# CEC1712H_S2_SX device description
Architecture: CORTEX-M4; Family: CEC1712H_S2_SX; Series: CEC1712H_S2_SX
Registers are 32-bit, read-write, reset 0x0 unless marked. A register's access mark holds for its fields unless they carry their own. Offsets are from the block's base; [hi:lo] are bit positions.

## WEEK — The Week Timer and the Sub-Week Timer assert the Power-Up Event Output which automatically powers-up the system from the G3 state
Instances: WEEK 0x4000AC80
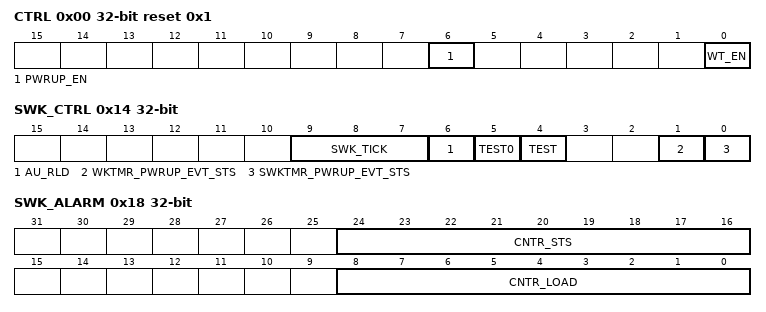
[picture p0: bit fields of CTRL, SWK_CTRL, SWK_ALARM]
0x00 CTRL reset 0x1 — Control Register
  [6] PWRUP_EN — This bit controls the state of the Power-Up Event Output and enables Week POWER-UP Event decoding in the VBAT-Powered Control Interface. 1=Power-Up Event Output Enabled. 0=Power-Up Event Output Disabled and Reset
  [0] WT_EN — The WT_ENABLE bit is used to start and stop the Week Alarm Counter Register and the Clock Divider Register. The value in the Counter Register is held when the WT_ENABLE bit is not asserted (0) and the count is resumed from the last value when the bit is asserted (1). The 15-Bit Clock Divider is reset to 00h and the Week Alarm Interface is in its lowest power consumption state when the WT_ENABLE bit is not asserted.
0x04 ALARM_CNT — Week Alarm Counter Register
  [27:0] WK_CNTR — While the WT_ENABLE bit is 1, this register is incremented at a 1 Hz rate. Writes of this register may require one second to take effect. Reads return the current state of the register. Reads and writes complete independently of the state of WT_ENABLE.
0x08 TMR_COMP reset 0xFFFFFFF — Week Timer Compare Register
  [27:0] WK_COMP — A Week Alarm Interrupt and a Week Alarm Power-Up Event are asserted when the Week Alarm Counter Register is greater than or equal to the contents of this register. Reads and writes complete independently of the state of WT_ENABLE.
0x0C CLKDIV — Clock Divider Register
  [14:0] DIV — Reads of this register return the current state of the Week Timer 15- bit clock divider.
0x10 SS_INTR_SEL — Sub-Second Programmable Interrupt Select Register
  [3:0] SPISR — This field determines the rate at which Sub-Second interrupt events are generated.
0x14 SWK_CTRL ro — Sub-Week Control Register
  [9:7] SWK_TICK — This field selects the clock source for the Sub-Week Counter.
  [6] AU_RLD — 1= No reload occurs when the Sub-Week Counter expires. 0= Reloads the SUBWEEK_COUNTER_LOAD field into the Sub- Week Counter when the counter expires.
  [5] TEST0 — Test
  [4] TEST
  [1] WKTMR_PWRUP_EVT_STS — This bit is set to 1 when the Week Alarm Counter Register is greater than or equal the contents of the Week Timer Compare. Register and the POWERUP_EN is 1. Writes of 1 clear this bit. Writes of 0 have no effect. Note: This bit does not have to be cleared to remove a Week Timer Power-Up Event.
  [0] SWKTMR_PWRUP_EVT_STS — This bit is set to 1 when the Sub-Week Alarm Counter Register decrements from 1 to 0 and the POWERUP_EN is 1. Writes of 1 clear this bit. Writes of 0 have no effect. Note: This bit MUST be cleared to remove a Sub-Week Timer Power-Up Event.
0x18 SWK_ALARM ro — Sub-Week Alarm Counter Register
  [24:16] CNTR_STS — Reads of this register return the current state of the 9-bit Sub-Week Alarm counter.
  [8:0] CNTR_LOAD — Writes with a non-zero value to this field reload the 9-bit Sub-Week Alarm counter. Writes of 0 disable the counter. If the Sub-Week Alarm counter decrements to 0 and the AUTO_RELOAD bit is set, the value in this field is automatically loaded into the Sub-Week Alarm counter.

## TACH — This block monitors TACH output signals from various types of fans, and determines their speed.
Instances: TACH0 0x40006000, TACH1 0x40006010
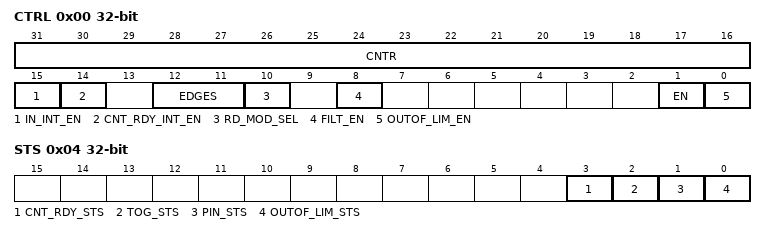
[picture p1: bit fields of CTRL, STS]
0x00 CTRL — TACHx Control Register
  [31:16] CNTR — This 16-bit field contains the latched value of the internal Tach pulse counter, which may be configured by the Tach Reading Mode Select field to operate as a free-running counter or to be gated by the Tach input signal.
  [15] IN_INT_EN — TACH_INPUT_INT_EN 1=Enable Tach Input toggle interrupt from Tach block, 0=Disable Tach Input toggle interrupt from Tach block
  [14] CNT_RDY_INT_EN — COUNT_READY_INT_EN 1=Enable Count Ready interrupt from Tach block, 0=Disable Count Ready interrupt from Tach block
  [12:11] EDGES — TACH_EDGES A Tach signal is a square wave with a 50 percent duty cycle. Typically, two Tach periods represents one revolution of the fan. A Tach period consists of three Tach edges. This programmed value represents the number of Tach edges that will be used to determine the interval for which the number of 100kHz_Clk pulses will be counted. 11b=9 Tach edges (4 Tach periods). 10b=5 Tach edges (2 Tach periods). 01b=3 Tach edges (1 Tach period). 00b=2 Tach edges (1/2 Tach period)
  [10] RD_MOD_SEL — TACH_READING_MODE_SELECT. 1=Counter is incremented on the rising edge of the 100kHz_Clk input. The counter is latched into the TACHX_COUNTER field and reset when the programmed number of edges is detected. 0=Counter is incremented when Tach Input transitions from low-tohigh state (default)
  [8] FILT_EN — FILTER_ENABLE This filter is used to remove high frequency glitches from Tach Input. When this filter is enabled, Tach input pulses less than two 100kHz_- Clk periods wide get filtered. 1= Filter enabled. 0= Filter disabled (default). It is recommended that the Tach input filter always be enabled.
  [1] EN — TACH_ENABLE 1= TACH Monitoring enabled, clocks enabled. 0= TACH Idle, clocks gated
  [0] OUTOF_LIM_EN — TACH_OUT_OF_LIMIT_ENABLE This bit is used to enable the TACH_OUT_OF_LIMIT_STATUS bit in the TACHx Status Register to generate an interrupt event. 1=Enable interrupt output from Tach block. 0=Disable interrupt output from Tach block (default)
0x04 STS — TACHx Status Register
  [3] CNT_RDY_STS — COUNT_READY_STATUS 1=Reading ready, 0=Reading not ready
  [2] TOG_STS — TOGGLE_STATUS 1=Tach Input changed state (this bit is set on a low-to-high or high-tolow transition), 0=Tach stable (R/WC)
  [1] PIN_STS — TACH_PIN_STATUS 1= Tach Input is high, 0= Tach Input is low
  [0] OUTOF_LIM_STS — TACH_OUT_OF_LIMIT_STATUS 1=Tach is outside of limits, 0=Tach is within limits (R/WC)
0x08 LIM_HI reset 0xFFFF — TACH HIGH LIMIT Register
  [15:0] T_HIGH — This value is compared with the value in the TACHX_COUNTER field. If the value in the counter is greater than the value programmed in this register, the TACH_OUT_OF_LIMIT_STATUS bit will be set. The TACH_OUT_OF_LIMIT_STATUS status event may be enabled to generate an interrupt to the embedded controller via the TACH_OUT_OF_LIMIT_ENABLE bit in the TACHx Control Register.
0x0C LIM_LO — TACHx Low Limit Register
  [15:0] T_LOW — This value is compared with the value in the TACHX_COUNTER field of the TACHx Control Register. If the value in the counter is less than the value programmed in this register, the TACH_OUT_OF_LIMIT_STATUS bit will be set. The TACH_OUT_OF_LIMIT_STATUS status event may be enabled to generate an interrupt to the embedded controller via the TACH_OUT_OF_LIMIT_ENABLE bit in the TACHx. Control Register To disable the TACH_OUT_OF_LIMIT_STATUS low event, program 0000h into this register.
